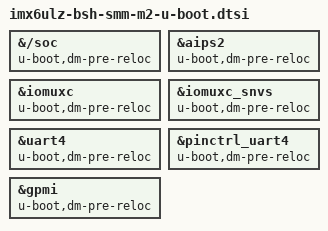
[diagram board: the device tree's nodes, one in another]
// SPDX-License-Identifier: GPL-2.0
/*
 * Copyright (C) 2022 BSH Hausgeraete GmbH
 *
 * Author: Michael Trimarchi <michael@amarulasolutions.com>
 */

&{/soc} {
	u-boot,dm-pre-reloc;
};

&aips2 {
	u-boot,dm-pre-reloc;
};

&iomuxc {
	u-boot,dm-pre-reloc;
};

&iomuxc_snvs {
	u-boot,dm-pre-reloc;
};

&uart4 {
	u-boot,dm-pre-reloc;
};

&pinctrl_uart4 {
	u-boot,dm-pre-reloc;
};

&gpmi {
	u-boot,dm-spl;
	u-boot,dm-pre-reloc;
};
